VERSION ""

NS_ :

BS_:

BU_: SENSOR_BOARD GATEWAY_NODE

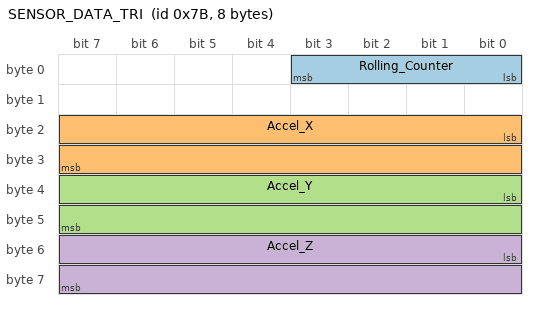
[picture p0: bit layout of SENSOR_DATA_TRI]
BO_ 123 SENSOR_DATA_TRI: 8 SENSOR_BOARD
 SG_ Rolling_Counter : 0|4@1+ (1,0) [0|15] "" GATEWAY_NODE
 SG_ Accel_X : 16|16@1- (0.1,0) [-204.8|204.7] "G" GATEWAY_NODE
 SG_ Accel_Y : 32|16@1- (0.1,0) [-204.8|204.7] "G" GATEWAY_NODE
 SG_ Accel_Z : 48|16@1- (0.1,0) [-204.8|204.7] "G" GATEWAY_NODE

BA_DEF_  "BusType" STRING ;
BA_DEF_DEF_  "BusType" "CAN";
